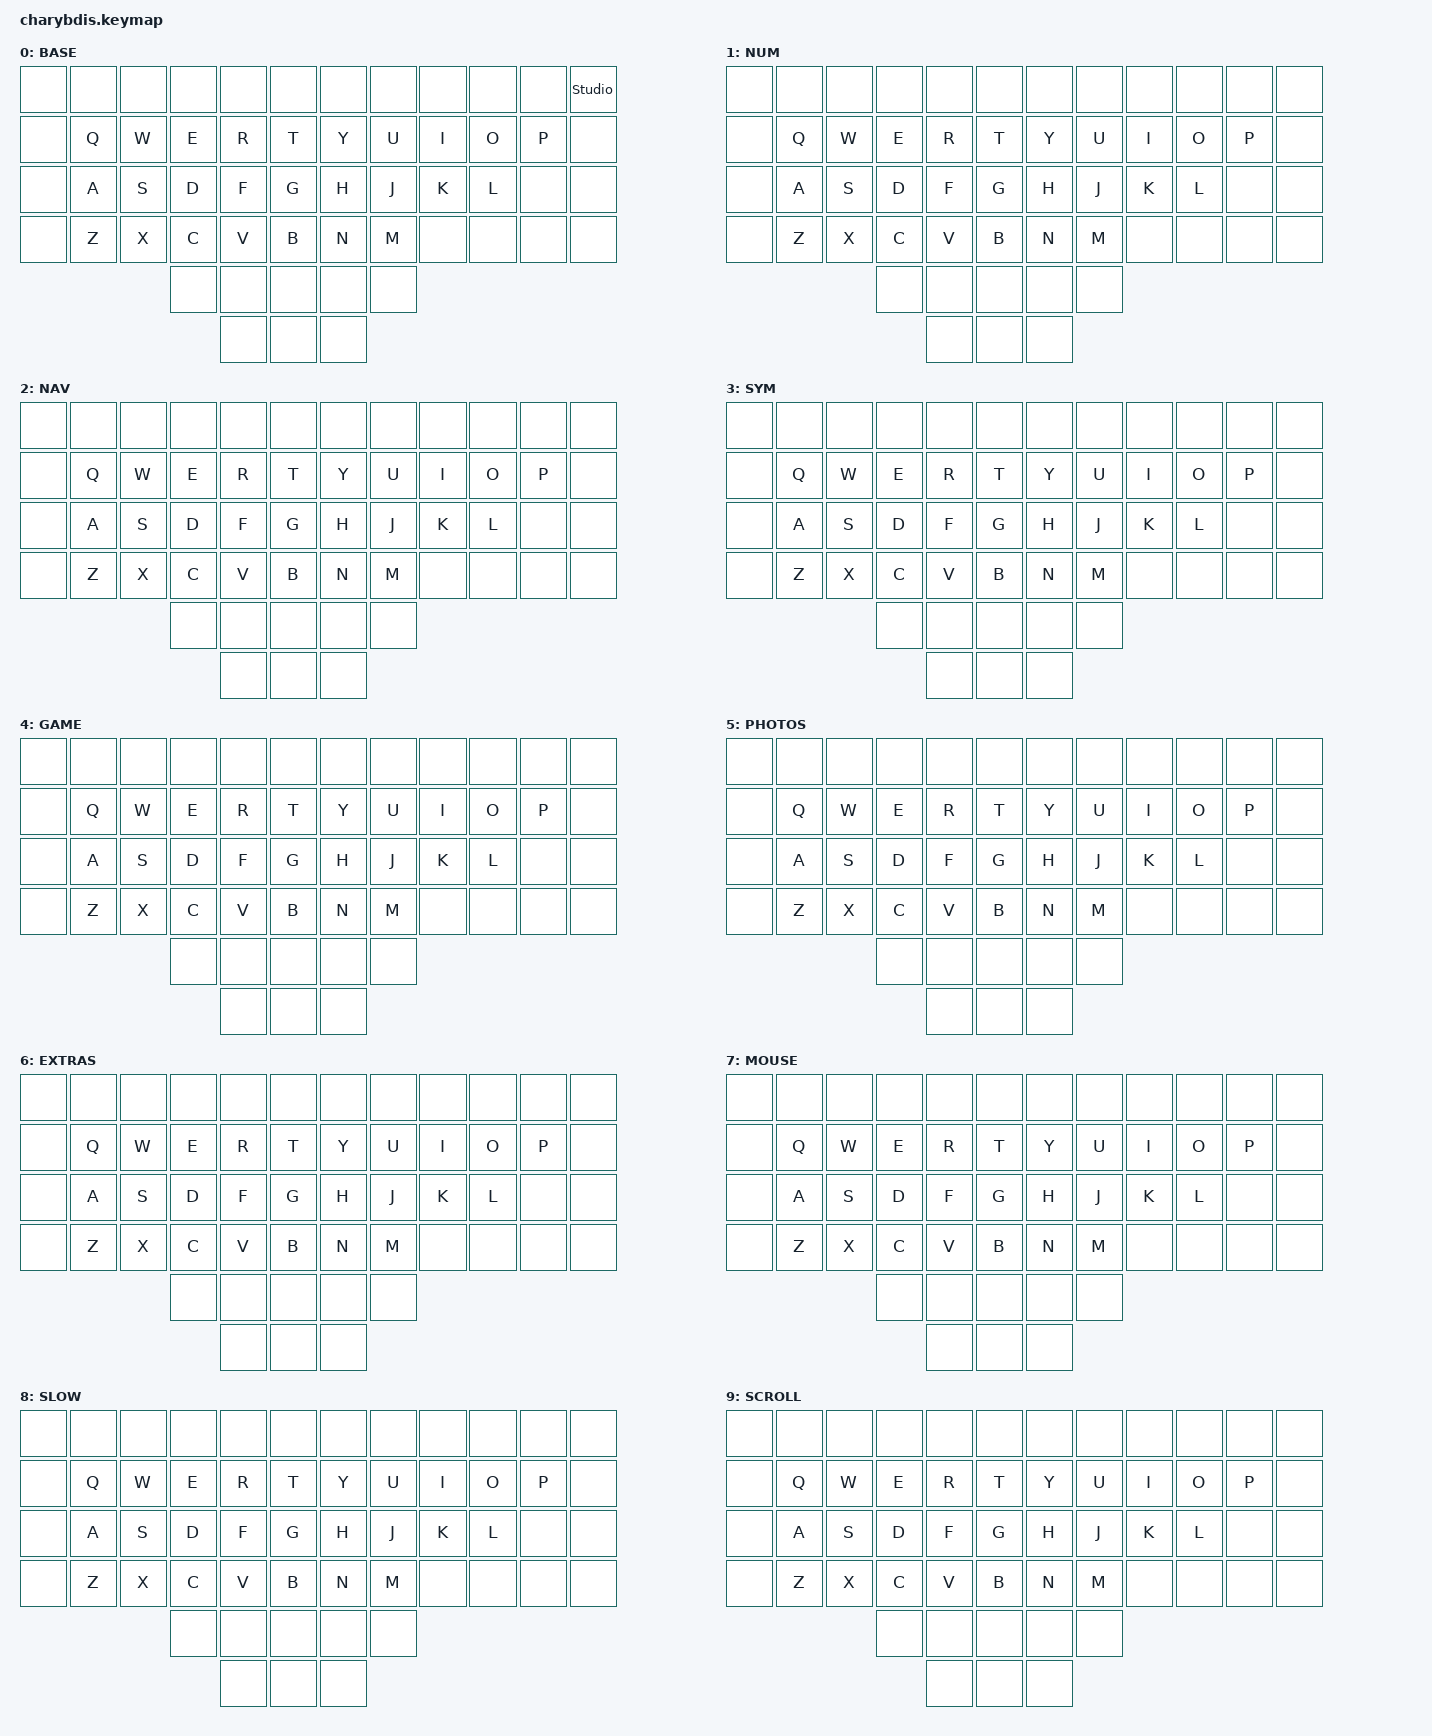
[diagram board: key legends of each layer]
#include <behaviors.dtsi>
#include <dt-bindings/zmk/bt.h>
#include <dt-bindings/zmk/keys.h>
#include <dt-bindings/zmk/mouse.h>
#include <dt-bindings/zmk/outputs.h>
#include <behaviors/mouse_keys.dtsi>
#include <dt-bindings/zmk/ext_power.h>
#include "macros.dtsi"
#include "behaviors.dtsi"
#include "combos.dtsi"

/ {
    /* input config for mouse move mode */
    trackball_listener {
        compatible = "zmk,input-behavior-listener";
        device = <&vtrackball>;
        layers = <0 2 7>;
        evt-type = <INPUT_EV_REL>;
        x-input-code = <INPUT_REL_X>;
        y-input-code = <INPUT_REL_Y>;
        scale-multiplier = <4>;
        scale-divisor = <5>;
        // bindings = <&ib_toggle_layer 7>;
    };

    /* input config for snipe mode */
    trackball_snipe_listener {
        compatible = "zmk,input-behavior-listener";   
        device = <&vtrackball>;
        layers = <8>;
        evt-type = <INPUT_EV_REL>;
        x-input-code = <INPUT_REL_X>;
        y-input-code = <INPUT_REL_Y>;
        scale-multiplier = <1>;
        scale-divisor = <6>;
    };

    /* input config for mouse scroll mode */
    trackball_scroll_listener {
        compatible = "zmk,input-behavior-listener";
        device = <&vtrackball>;
        layers = <9>;
        evt-type = <INPUT_EV_REL>;            
        x-input-code = <INPUT_REL_MISC>;
        y-input-code = <INPUT_REL_WHEEL>;
        y-invert;
        bindings = <&ib_wheel_scaler 1 14>;
    };

    /* define a resolution down scaler only for INPUT_REL_WHEEL */
    ib_wheel_scaler: ib_wheel_scaler {
        compatible = "zmk,input-behavior-scaler";
        #binding-cells = <2>;
        evt-type = <INPUT_EV_REL>;
        input-code = <INPUT_REL_WHEEL>;
    };

    /* adjust cooldown waiting period for mouse key layer after activated */
    ib_toggle_layer: ib_toggle_layer {
        compatible = "zmk,input-behavior-tog-layer";
        #binding-cells = <1>;
        time-to-live-ms = <750>;
    };
// +----+----+----+----+----+----+   +----+----+----+----+----+----+
//   00   01   02   03   04   05       11   10   09   08   07   06
// +----+----+----+----+----+----+   +----+----+----+----+----+----+
//   12   13   14   15   16   17       23   22   21   20   19   18
// +----+----+----+----+----+----+   +----+----+----+----+----+----+
//   24   25   26   27   28   29       35   34   33   32   31   30
// +----+----+----+----+----+----+   +----+----+----+----+----+----+
//   36   37   38   39   40   41       47   46   45   44   43   42
// +----+----+----+----+----+----+   +----+----+----+----+----+----+
//                  48   49   50       52   51
//                +----+----+----+   +----+----+
//                       53   54       55
//                     +----+----+   +----+
// #define BASE    0
// #define NUM     1
// #define NAV     2
// #define SYM     3
// #define GAME    4
// #define PHOTOS  5
// #define EXTRAS  6
// #define MOUSE   7
// #define SLOW    8
// #define SCROLL  9

    keymap {
        compatible = "zmk,keymap";
        BASE {
            bindings = <
               &none &none &none &none &none &none  &none &none &none &none &none &studio_unlock
               &none &kp Q &kp W &kp E &kp R &kp T  &kp Y &kp U &kp I &kp O &kp P &none
               &none &kp A &kp S &kp D &kp F &kp G  &kp H &kp J &kp K &kp L &none &none
               &none &kp Z &kp X &kp C &kp V &kp B  &kp N &kp M &none &none &none &none
                                 &none &none &none  &none &none
                                       &none &none  &none
            >;
        };

        NUM {
            bindings = <
               &none &none &none &none &none &none  &none &none &none &none &none &none
               &none &kp Q &kp W &kp E &kp R &kp T  &kp Y &kp U &kp I &kp O &kp P &none
               &none &kp A &kp S &kp D &kp F &kp G  &kp H &kp J &kp K &kp L &none &none
               &none &kp Z &kp X &kp C &kp V &kp B  &kp N &kp M &none &none &none &none
                                 &none &none &none  &none &none
                                       &none &none  &none
            >;
        };

        NAV {
            bindings = <
               &none &none &none &none &none &none  &none &none &none &none &none &none
               &none &kp Q &kp W &kp E &kp R &kp T  &kp Y &kp U &kp I &kp O &kp P &none
               &none &kp A &kp S &kp D &kp F &kp G  &kp H &kp J &kp K &kp L &none &none
               &none &kp Z &kp X &kp C &kp V &kp B  &kp N &kp M &none &none &none &none
                                 &none &none &none  &none &none
                                       &none &none  &none
            >;
        };

        SYM {
            bindings = <
               &none &none &none &none &none &none  &none &none &none &none &none &none
               &none &kp Q &kp W &kp E &kp R &kp T  &kp Y &kp U &kp I &kp O &kp P &none
               &none &kp A &kp S &kp D &kp F &kp G  &kp H &kp J &kp K &kp L &none &none
               &none &kp Z &kp X &kp C &kp V &kp B  &kp N &kp M &none &none &none &none
                                 &none &none &none  &none &none
                                       &none &none  &none
            >;
        };

        GAME {
            bindings = <
               &none &none &none &none &none &none  &none &none &none &none &none &none
               &none &kp Q &kp W &kp E &kp R &kp T  &kp Y &kp U &kp I &kp O &kp P &none
               &none &kp A &kp S &kp D &kp F &kp G  &kp H &kp J &kp K &kp L &none &none
               &none &kp Z &kp X &kp C &kp V &kp B  &kp N &kp M &none &none &none &none
                                 &none &none &none  &none &none
                                       &none &none  &none
            >;
        };

        PHOTOS {
            bindings = <
               &none &none &none &none &none &none  &none &none &none &none &none &none
               &none &kp Q &kp W &kp E &kp R &kp T  &kp Y &kp U &kp I &kp O &kp P &none
               &none &kp A &kp S &kp D &kp F &kp G  &kp H &kp J &kp K &kp L &none &none
               &none &kp Z &kp X &kp C &kp V &kp B  &kp N &kp M &none &none &none &none
                                 &none &none &none  &none &none
                                       &none &none  &none
            >;
        };

        EXTRAS {
            bindings = <
               &none &none &none &none &none &none  &none &none &none &none &none &none
               &none &kp Q &kp W &kp E &kp R &kp T  &kp Y &kp U &kp I &kp O &kp P &none
               &none &kp A &kp S &kp D &kp F &kp G  &kp H &kp J &kp K &kp L &none &none
               &none &kp Z &kp X &kp C &kp V &kp B  &kp N &kp M &none &none &none &none
                                 &none &none &none  &none &none
                                       &none &none  &none
            >;
        };

        MOUSE {
            bindings = <
               &none &none &none &none &none &none  &none &none &none &none &none &none
               &none &kp Q &kp W &kp E &kp R &kp T  &kp Y &kp U &kp I &kp O &kp P &none
               &none &kp A &kp S &kp D &kp F &kp G  &kp H &kp J &kp K &kp L &none &none
               &none &kp Z &kp X &kp C &kp V &kp B  &kp N &kp M &none &none &none &none
                                 &none &none &none  &none &none
                                       &none &none  &none
            >;
        };

        SLOW {
            bindings = <
               &none &none &none &none &none &none  &none &none &none &none &none &none
               &none &kp Q &kp W &kp E &kp R &kp T  &kp Y &kp U &kp I &kp O &kp P &none
               &none &kp A &kp S &kp D &kp F &kp G  &kp H &kp J &kp K &kp L &none &none
               &none &kp Z &kp X &kp C &kp V &kp B  &kp N &kp M &none &none &none &none
                                 &none &none &none  &none &none
                                       &none &none  &none
            >;
        };

        SCROLL {
            bindings = <
               &none &none &none &none &none &none  &none &none &none &none &none &none
               &none &kp Q &kp W &kp E &kp R &kp T  &kp Y &kp U &kp I &kp O &kp P &none
               &none &kp A &kp S &kp D &kp F &kp G  &kp H &kp J &kp K &kp L &none &none
               &none &kp Z &kp X &kp C &kp V &kp B  &kp N &kp M &none &none &none &none
                                 &none &none &none  &none &none
                                       &none &none  &none
            >;
        };
    };
};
